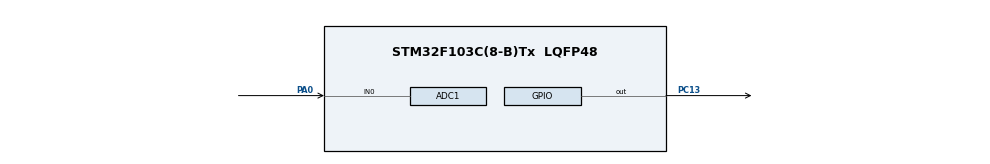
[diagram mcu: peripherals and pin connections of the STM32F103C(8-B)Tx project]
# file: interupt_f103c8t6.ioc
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ADC1.AWD1HighThreshold=4095
ADC1.AWD1ITMode=ENABLE
ADC1.AWD1LowThreshold=3500
ADC1.Channel-2\#ChannelInjectedConversion=ADC_CHANNEL_0
ADC1.Channel-5\#ChannelInjectedConversion=ADC_CHANNEL_0
ADC1.ContinuousConvMode=DISABLE
ADC1.EnableAnalogWatchDog=true
ADC1.EnableInjectedConversion=ENABLE
ADC1.EnableRegularConversion=DISABLE
ADC1.InjNumberOfConversion=2
ADC1.InjectedConvMode=AutoInjected
ADC1.InjectedOffset-2\#ChannelInjectedConversion=0
ADC1.InjectedOffset-5\#ChannelInjectedConversion=0
ADC1.Rank-2\#ChannelInjectedConversion=1
ADC1.Rank-5\#ChannelInjectedConversion=2
ADC1.SamplingTime-2\#ChannelInjectedConversion=ADC_SAMPLETIME_28CYCLES_5
ADC1.SamplingTime-5\#ChannelInjectedConversion=ADC_SAMPLETIME_28CYCLES_5
ADC1.master=1
Mcu.Family=STM32F1
Mcu.Name=STM32F103C(8-B)Tx
Mcu.Package=LQFP48
NVIC.PriorityGroup=NVIC_PRIORITYGROUP_4
PA0-WKUP.Signal=ADCx_IN0
PA13.Mode=Serial_Wire
PA13.Signal=SYS_JTMS-SWDIO
PA14.Mode=Serial_Wire
PA14.Signal=SYS_JTCK-SWCLK
PC13-TAMPER-RTC.Signal=GPIO_Output
PC14-OSC32_IN.Mode=LSE-External-Oscillator
PC14-OSC32_IN.Signal=RCC_OSC32_IN
PC15-OSC32_OUT.Mode=LSE-External-Oscillator
PC15-OSC32_OUT.Signal=RCC_OSC32_OUT
PD0-OSC_IN.Mode=HSE-External-Oscillator
PD0-OSC_IN.Signal=RCC_OSC_IN
PD1-OSC_OUT.Mode=HSE-External-Oscillator
PD1-OSC_OUT.Signal=RCC_OSC_OUT
ProjectManager.HeapSize=0x200
ProjectManager.StackSize=0x400
ProjectManager.TargetToolchain=STM32CubeIDE
RCC.APB1Freq_Value=8000000
RCC.APB2Freq_Value=8000000
SH.ADCx_IN0.0=ADC1_IN0,IN0
board=custom

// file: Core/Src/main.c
/* USER CODE BEGIN Header */
/**
  ******************************************************************************
  * @file           : main.c
  * @brief          : Main program body
  ******************************************************************************
  * @attention
  *
  * <h2><center>&copy; Copyright (c) 2020 STMicroelectronics.
  * All rights reserved.</center></h2>
  *
  * This software component is licensed by ST under BSD 3-Clause license,
  * the "License"; You may not use this file except in compliance with the
  * License. You may obtain a copy of the License at:
  *                        opensource.org/licenses/BSD-3-Clause
  *
  ******************************************************************************
  */
/* USER CODE END Header */

#include "main.h"

ADC_HandleTypeDef hadc1;

void SystemClock_Config(void);
static void MX_GPIO_Init(void);
static void MX_ADC1_Init(void);

int main(void)
{

  /* MCU Configuration--------------------------------------------------------*/

  /* Reset of all peripherals, Initializes the Flash interface and the Systick. */
  HAL_Init();

  /* Configure the system clock */
  SystemClock_Config();

  /* Initialize all configured peripherals */
  MX_GPIO_Init();
  MX_ADC1_Init();
  /* USER CODE BEGIN 2 */
  HAL_GPIO_WritePin(GPIOC, GPIO_PIN_13, GPIO_PIN_RESET);
  /* USER CODE END 2 */

  /* Infinite loop */
  while (1)
  {

  }
}

void SystemClock_Config(void)
{
  RCC_OscInitTypeDef RCC_OscInitStruct = {0};
  RCC_ClkInitTypeDef RCC_ClkInitStruct = {0};
  RCC_PeriphCLKInitTypeDef PeriphClkInit = {0};

  /** Initializes the CPU, AHB and APB busses clocks
  */
  RCC_OscInitStruct.OscillatorType = RCC_OSCILLATORTYPE_HSI;
  RCC_OscInitStruct.HSIState = RCC_HSI_ON;
  RCC_OscInitStruct.HSICalibrationValue = RCC_HSICALIBRATION_DEFAULT;
  RCC_OscInitStruct.PLL.PLLState = RCC_PLL_NONE;
  if (HAL_RCC_OscConfig(&RCC_OscInitStruct) != HAL_OK)
  {
    Error_Handler();
  }
  /** Initializes the CPU, AHB and APB busses clocks
  */
  RCC_ClkInitStruct.ClockType = RCC_CLOCKTYPE_HCLK|RCC_CLOCKTYPE_SYSCLK
                              |RCC_CLOCKTYPE_PCLK1|RCC_CLOCKTYPE_PCLK2;
  RCC_ClkInitStruct.SYSCLKSource = RCC_SYSCLKSOURCE_HSI;
  RCC_ClkInitStruct.AHBCLKDivider = RCC_SYSCLK_DIV1;
  RCC_ClkInitStruct.APB1CLKDivider = RCC_HCLK_DIV1;
  RCC_ClkInitStruct.APB2CLKDivider = RCC_HCLK_DIV1;

  if (HAL_RCC_ClockConfig(&RCC_ClkInitStruct, FLASH_LATENCY_0) != HAL_OK)
  {
    Error_Handler();
  }
  PeriphClkInit.PeriphClockSelection = RCC_PERIPHCLK_ADC;
  PeriphClkInit.AdcClockSelection = RCC_ADCPCLK2_DIV2;
  if (HAL_RCCEx_PeriphCLKConfig(&PeriphClkInit) != HAL_OK)
  {
    Error_Handler();
  }
}

static void MX_ADC1_Init(void)
{

  ADC_AnalogWDGConfTypeDef AnalogWDGConfig = {0};
  ADC_InjectionConfTypeDef sConfigInjected = {0};

  /** Common config
  */
  hadc1.Instance = ADC1;
  hadc1.Init.ScanConvMode = ADC_SCAN_ENABLE;
  hadc1.Init.ContinuousConvMode = DISABLE;
  hadc1.Init.DiscontinuousConvMode = DISABLE;
  hadc1.Init.ExternalTrigConv = ADC_SOFTWARE_START;
  hadc1.Init.DataAlign = ADC_DATAALIGN_RIGHT;
  hadc1.Init.NbrOfConversion = 1;
  if (HAL_ADC_Init(&hadc1) != HAL_OK)
  {
    Error_Handler();
  }
  /** Configure Analog WatchDog 1
  */
  AnalogWDGConfig.WatchdogMode = ADC_ANALOGWATCHDOG_SINGLE_INJEC;
  AnalogWDGConfig.HighThreshold = 4095;
  AnalogWDGConfig.LowThreshold = 3500;
  AnalogWDGConfig.Channel = ADC_CHANNEL_0;
  AnalogWDGConfig.ITMode = ENABLE;
  if (HAL_ADC_AnalogWDGConfig(&hadc1, &AnalogWDGConfig) != HAL_OK)
  {
    Error_Handler();
  }
  /** Configure Injected Channel
  */
  sConfigInjected.InjectedChannel = ADC_CHANNEL_0;
  sConfigInjected.InjectedRank = ADC_INJECTED_RANK_1;
  sConfigInjected.InjectedNbrOfConversion = 2;
  sConfigInjected.InjectedSamplingTime = ADC_SAMPLETIME_28CYCLES_5;
  sConfigInjected.ExternalTrigInjecConv = ADC_INJECTED_SOFTWARE_START;
  sConfigInjected.AutoInjectedConv = ENABLE;
  sConfigInjected.InjectedDiscontinuousConvMode = DISABLE;
  sConfigInjected.InjectedOffset = 0;
  if (HAL_ADCEx_InjectedConfigChannel(&hadc1, &sConfigInjected) != HAL_OK)
  {
    Error_Handler();
  }
  /** Configure Injected Channel
  */
  sConfigInjected.InjectedRank = ADC_INJECTED_RANK_2;
  if (HAL_ADCEx_InjectedConfigChannel(&hadc1, &sConfigInjected) != HAL_OK)
  {
    Error_Handler();
  }
  /* USER CODE BEGIN ADC1_Init 2 */
  HAL_ADCEx_Calibration_Start(&hadc1);
  HAL_ADCEx_InjectedStart_IT(&hadc1);
  /* USER CODE END ADC1_Init 2 */

}

static void MX_GPIO_Init(void)
{
  GPIO_InitTypeDef GPIO_InitStruct = {0};

  /* GPIO Ports Clock Enable */
  __HAL_RCC_GPIOC_CLK_ENABLE();
  __HAL_RCC_GPIOD_CLK_ENABLE();
  __HAL_RCC_GPIOA_CLK_ENABLE();

  /*Configure GPIO pin Output Level */
  HAL_GPIO_WritePin(GPIOC, GPIO_PIN_13, GPIO_PIN_RESET);

  /*Configure GPIO pin : PC13 */
  GPIO_InitStruct.Pin = GPIO_PIN_13;
  GPIO_InitStruct.Mode = GPIO_MODE_OUTPUT_PP;
  GPIO_InitStruct.Pull = GPIO_NOPULL;
  GPIO_InitStruct.Speed = GPIO_SPEED_FREQ_LOW;
  HAL_GPIO_Init(GPIOC, &GPIO_InitStruct);

}

/* USER CODE BEGIN 4 */
/*void HAL_GPIO_EXTI_Callback(uint16_t GPIO_Pin) {
  if(GPIO_Pin== GPIO_PIN_1) {
 	  HAL_GPIO_TogglePin(GPIOC, GPIO_PIN_13);
  } else {
    __NOP();
  }
}*/
void HAL_ADC_LevelOutOfWindowCallback(ADC_HandleTypeDef* hadc1)
{
	for (int i = 0; i < 6; i++)
	{
		HAL_GPIO_TogglePin(GPIOC, GPIO_PIN_13);
		HAL_Delay(250);
	}
}
/* USER CODE END 4 */

void Error_Handler(void)
{
}

/************************ (C) COPYRIGHT STMicroelectronics *****END OF FILE****/
